# STM32H7RSxx register map
File version: 0.1
CPU: CM7 r0p1, little endian, MPU, FPU, 4 interrupt priority bits
Registers are 32-bit, read-write, reset 0x0 unless marked. A register's access mark holds for its fields unless they carry their own. Offsets are from the block's base; [hi:lo] are bit positions; {n}, {i} and the like mark numbered series.

## RCC
Base 0x58024400
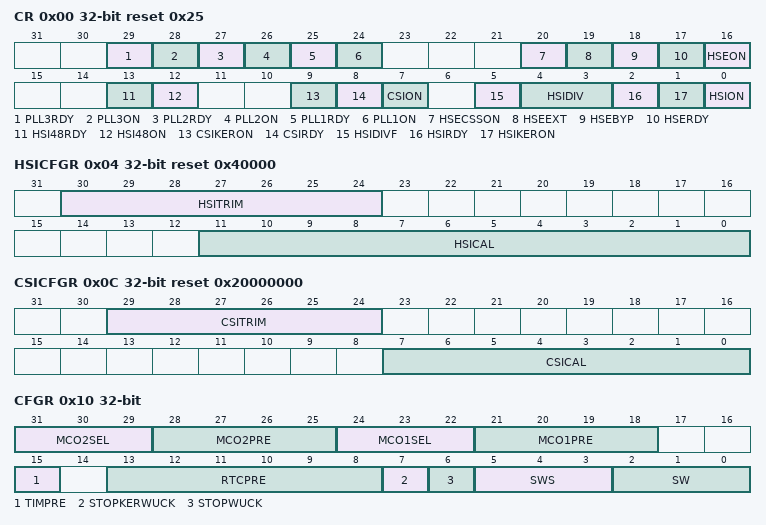
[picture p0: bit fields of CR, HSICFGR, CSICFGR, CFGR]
0x00 CR reset 0x25 — Control register
  [29] PLL3RDY, [28] PLL3ON, [27] PLL2RDY, [26] PLL2ON, [25] PLL1RDY ro, [24] PLL1ON, [20] HSECSSON, [19] HSEEXT, [18] HSEBYP, [17] HSERDY ro, [16] HSEON, [13] HSI48RDY ro, [12] HSI48ON, [9] CSIKERON, [8] CSIRDY ro, [7] CSION, [5] HSIDIVF ro, [4:3] HSIDIV, [2] HSIRDY ro, [1] HSIKERON, [0] HSION
0x04 HSICFGR access not given reset 0x40000 — RCC HSI calibration register
  [30:24] HSITRIM, [11:0] HSICAL
0x08 CRRCR access not given — RCC clock recovery RC register
  [9:0] HSI48CAL
0x0C CSICFGR access not given reset 0x20000000 — RCC CSI calibration register
  [29:24] CSITRIM, [7:0] CSICAL
0x10 CFGR access not given — RCC clock configuration register
  [31:29] MCO2SEL
  [28:25] MCO2PRE
  [24:22] MCO1SEL
  [21:18] MCO1PRE
  [15] TIMPRE
  [13:8] RTCPRE
  [7] STOPKERWUCK — STOPWUCK
  [6] STOPWUCK
  [5:3] SWS ro
  [2:0] SW
0x18 CDCFGR access not given — RCC CPU domain clcok configuration register
  [3:0] CPRE
0x1C BMCFGR access not given — RCC AHB configuration register
  [3:0] BMPRE
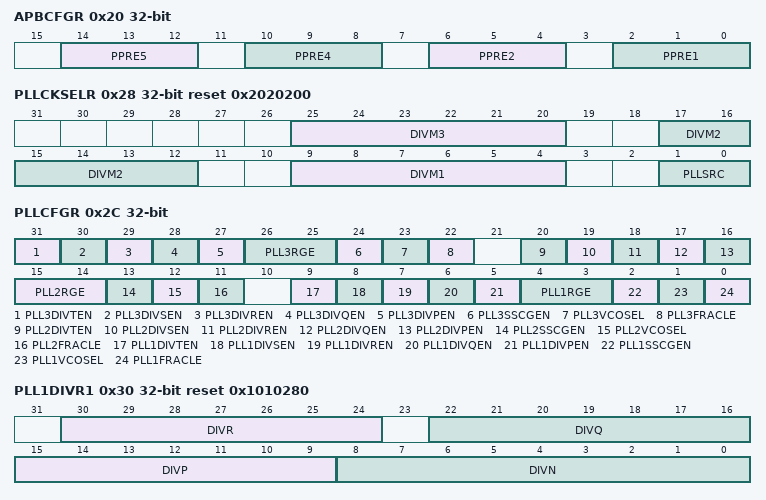
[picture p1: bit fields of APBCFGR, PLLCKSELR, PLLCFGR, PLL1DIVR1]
0x20 APBCFGR access not given — RCC APB clocks configuration register
  [14:12] PPRE5, [10:8] PPRE4, [6:4] PPRE2, [2:0] PPRE1
0x28 PLLCKSELR access not given reset 0x2020200 — RCC PLL clock source selection register
  [25:20] DIVM3 — prescaler for PLL3
  [17:12] DIVM2 — prescaler for PLL2
  [9:4] DIVM1 — prescaler for PLL1
  [1:0] PLLSRC
0x2C PLLCFGR access not given — RCC PLLs configuration register
  [31] PLL3DIVTEN — PLL3 DIVT divider output enable
  [30] PLL3DIVSEN — PLL3 DIVS divider output enable
  [29] PLL3DIVREN — PLL3 DIVR divider output enable
  [28] PLL3DIVQEN — PLL3 DIVQ divider output enable
  [27] PLL3DIVPEN — PLL3 DIVP divider output enable
  [26:25] PLL3RGE — PLL3 input frequency range
  [24] PLL3SSCGEN — PLL3 SSCG enable
  [23] PLL3VCOSEL — PLL3 VCO Selection
  [22] PLL3FRACLE — PLL3 fractionnal latch enable
  [20] PLL2DIVTEN — PLL2 DIVT divider output enable
  [19] PLL2DIVSEN — PLL2 DIVS divider output enable
  [18] PLL2DIVREN — PLL2 DIVR divider output enable
  [17] PLL2DIVQEN — PLL2 DIVQ divider output enable
  [16] PLL2DIVPEN — PLL2 DIVP divider output enable
  [15:14] PLL2RGE — PLL2 input frequency range
  [13] PLL2SSCGEN — PLL2 SSCG enable
  [12] PLL2VCOSEL — PLL2 VCO Selection
  [11] PLL2FRACLE — PLL2 fractionnal latch enable
  [9] PLL1DIVTEN — PLL1 DIVT divider output enable
  [8] PLL1DIVSEN — PLL1 DIVS divider output enable
  [7] PLL1DIVREN — PLL1 DIVR divider output enable
  [6] PLL1DIVQEN — PLL1 DIVQ divider output enable
  [5] PLL1DIVPEN — PLL1 DIVP divider output enable
  [4:3] PLL1RGE — PLL1 input frequency range
  [2] PLL1SSCGEN — PLL1 SSCG enable
  [1] PLL1VCOSEL — PLL1 VCO Selection
  [0] PLL1FRACLE — PLL1 fractionnal latch enable
0x30 PLL1DIVR1 access not given reset 0x1010280 — RCC PLL1 divider configuration register 1
  [30:24] DIVR, [22:16] DIVQ, [15:9] DIVP, [8:0] DIVN
{0x2C+8i} PLL{i}FRACR access not given (i=1..3) — RCC PLL{i} fractional divider register
  [15:3] FRACN
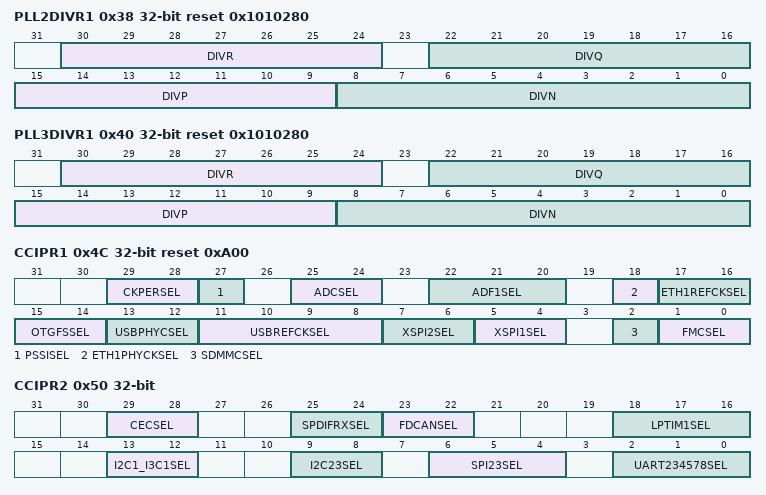
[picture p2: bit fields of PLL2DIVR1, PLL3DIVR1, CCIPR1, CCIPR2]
0x38 PLL2DIVR1 access not given reset 0x1010280 — RCC PLL2 dividers configuration register 1
  [30:24] DIVR, [22:16] DIVQ, [15:9] DIVP, [8:0] DIVN
0x40 PLL3DIVR1 access not given reset 0x1010280 — RCC PLL3 divider configuration register 1
  [30:24] DIVR, [22:16] DIVQ, [15:9] DIVP, [8:0] DIVN
0x4C CCIPR1 access not given reset 0xA00 — RCC AHB peripheral kernel clock selection register
  [29:28] CKPERSEL, [27] PSSISEL, [25:24] ADCSEL, [22:20] ADF1SEL, [18] ETH1PHYCKSEL, [17:16] ETH1REFCKSEL, [15:14] OTGFSSEL, [13:12] USBPHYCSEL, [11:8] USBREFCKSEL, [7:6] XSPI2SEL, [5:4] XSPI1SEL, [2] SDMMCSEL, [1:0] FMCSEL
0x50 CCIPR2 access not given — RCC APB1 peripheral kernel clock selection register
  [29:28] CECSEL, [25:24] SPDIFRXSEL, [23:22] FDCANSEL, [18:16] LPTIM1SEL, [13:12] I2C1_I3C1SEL, [9:8] I2C23SEL, [6:4] SPI23SEL, [2:0] UART234578SEL
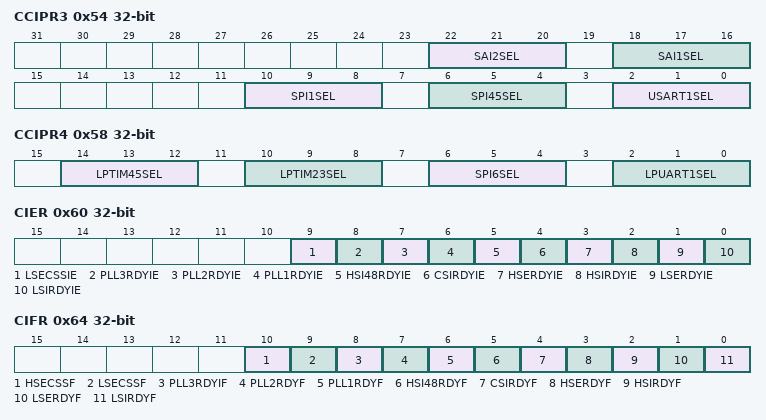
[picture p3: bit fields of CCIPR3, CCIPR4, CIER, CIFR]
0x54 CCIPR3 access not given — RCC APB2 peripheral kernel clock selection register
  [22:20] SAI2SEL, [18:16] SAI1SEL, [10:8] SPI1SEL, [6:4] SPI45SEL, [2:0] USART1SEL
0x58 CCIPR4 access not given — RCC APB4,5 peripheral kernel clock selection register
  [14:12] LPTIM45SEL, [10:8] LPTIM23SEL, [6:4] SPI6SEL, [2:0] LPUART1SEL
0x60 CIER access not given — RCC clock source interrupt enable register
  [9] LSECSSIE, [8] PLL3RDYIE, [7] PLL2RDYIE, [6] PLL1RDYIE, [5] HSI48RDYIE, [4] CSIRDYIE, [3] HSERDYIE, [2] HSIRDYIE, [1] LSERDYIE, [0] LSIRDYIE
0x64 CIFR ro — RCC clock source interrupt flag register
  [10] HSECSSF — LSECSSIF
  [9] LSECSSF
  [8] PLL3RDYIF
  [7] PLL2RDYF
  [6] PLL1RDYF
  [5] HSI48RDYF
  [4] CSIRDYF
  [3] HSERDYF
  [2] HSIRDYF
  [1] LSERDYF
  [0] LSIRDYF
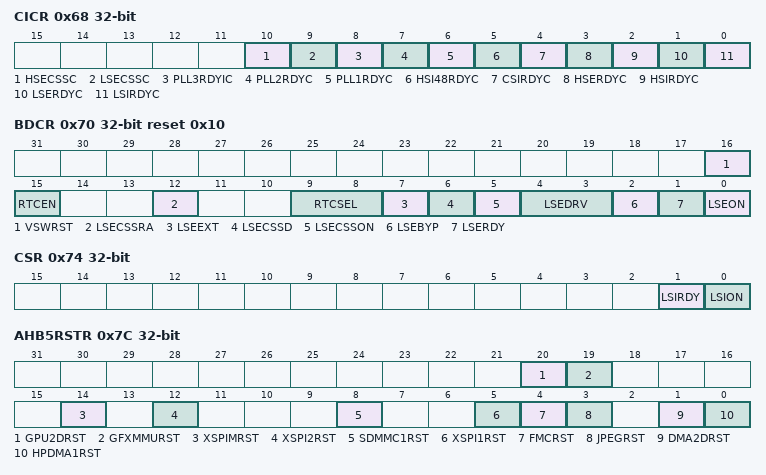
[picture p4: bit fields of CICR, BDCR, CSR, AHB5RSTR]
0x68 CICR access not given — RCC clock source interrupt clear register
  [10] HSECSSC — LSECSSIC
  [9] LSECSSC
  [8] PLL3RDYIC
  [7] PLL2RDYC
  [6] PLL1RDYC
  [5] HSI48RDYC
  [4] CSIRDYC
  [3] HSERDYC
  [2] HSIRDYC
  [1] LSERDYC
  [0] LSIRDYC
0x70 BDCR access not given reset 0x10 — RCC Backup domain control register
  [16] VSWRST, [15] RTCEN, [12] LSECSSRA, [9:8] RTCSEL, [7] LSEEXT, [6] LSECSSD, [5] LSECSSON, [4:3] LSEDRV, [2] LSEBYP, [1] LSERDY ro, [0] LSEON
0x74 CSR access not given — RCC clock control and status register
  [1] LSIRDY ro, [0] LSION
0x7C AHB5RSTR access not given — RCC AHB5 peripheral reset register
  [20] GPU2DRST, [19] GFXMMURST, [14] XSPIMRST, [12] XSPI2RST, [8] SDMMC1RST, [5] XSPI1RST, [4] FMCRST, [3] JPEGRST, [1] DMA2DRST, [0] HPDMA1RST
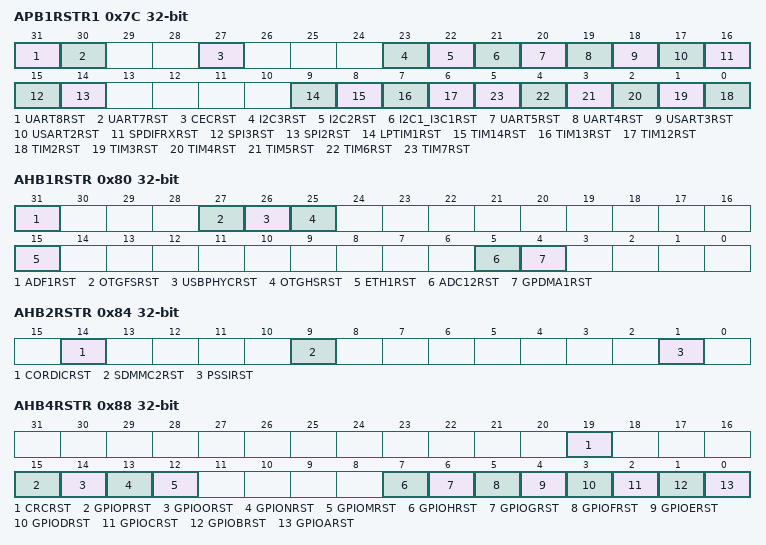
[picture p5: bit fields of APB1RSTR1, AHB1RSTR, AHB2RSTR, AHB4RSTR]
0x7C APB1RSTR1 access not given — RCC APB1 peripheral reset register 1
  [31] UART8RST, [30] UART7RST, [27] CECRST, [23] I2C3RST, [22] I2C2RST, [21] I2C1_I3C1RST, [20] UART5RST, [19] UART4RST, [18] USART3RST, [17] USART2RST, [16] SPDIFRXRST, [15] SPI3RST, [14] SPI2RST, [9] LPTIM1RST, [8] TIM14RST, [7] TIM13RST, [6] TIM12RST, [n-2] TIM{n}RST (n=2..7)
0x80 AHB1RSTR access not given — RCC AHB1 peripheral reset register
  [31] ADF1RST, [27] OTGFSRST, [26] USBPHYCRST, [25] OTGHSRST, [15] ETH1RST, [5] ADC12RST, [4] GPDMA1RST
0x84 AHB2RSTR access not given — RCC AHB2 peripheral reset register
  [14] CORDICRST, [9] SDMMC2RST, [1] PSSIRST
0x88 AHB4RSTR access not given — RCC AHB4 peripheral reset register
  [19] CRCRST, [15] GPIOPRST, [14] GPIOORST, [13] GPIONRST, [12] GPIOMRST, [7] GPIOHRST, [6] GPIOGRST, [5] GPIOFRST, [4] GPIOERST, [3] GPIODRST, [2] GPIOCRST, [1] GPIOBRST, [0] GPIOARST
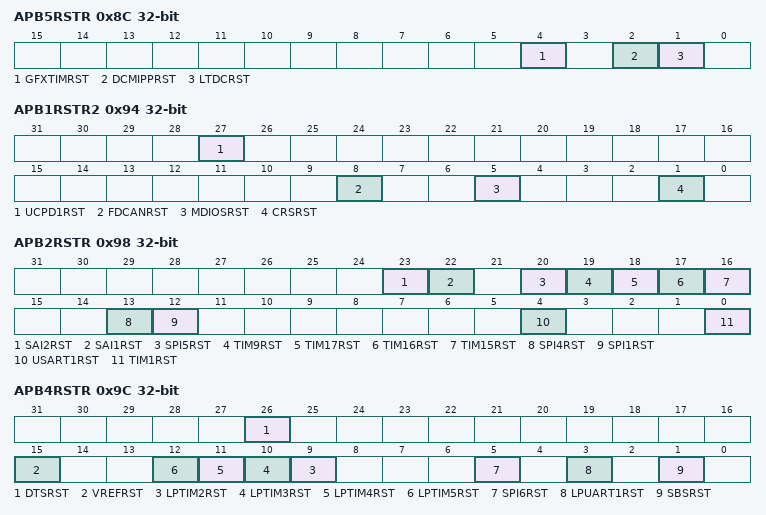
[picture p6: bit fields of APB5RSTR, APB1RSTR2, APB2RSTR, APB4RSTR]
0x8C APB5RSTR access not given — RCC APB5 peripheral reset register
  [4] GFXTIMRST, [2] DCMIPPRST, [1] LTDCRST
0x94 APB1RSTR2 access not given — RCC APB1 peripheral reset register 2
  [27] UCPD1RST, [8] FDCANRST, [5] MDIOSRST, [1] CRSRST
0x98 APB2RSTR access not given — RCC APB2 peripheral reset register
  [23] SAI2RST, [22] SAI1RST, [20] SPI5RST, [19] TIM9RST, [18] TIM17RST, [17] TIM16RST, [16] TIM15RST, [13] SPI4RST, [12] SPI1RST, [4] USART1RST, [0] TIM1RST
0x9C APB4RSTR access not given — RCC APB4 peripheral reset register
  [26] DTSRST, [15] VREFRST, [n+7] LPTIM{n}RST (n=2..5), [5] SPI6RST, [3] LPUART1RST, [1] SBSRST
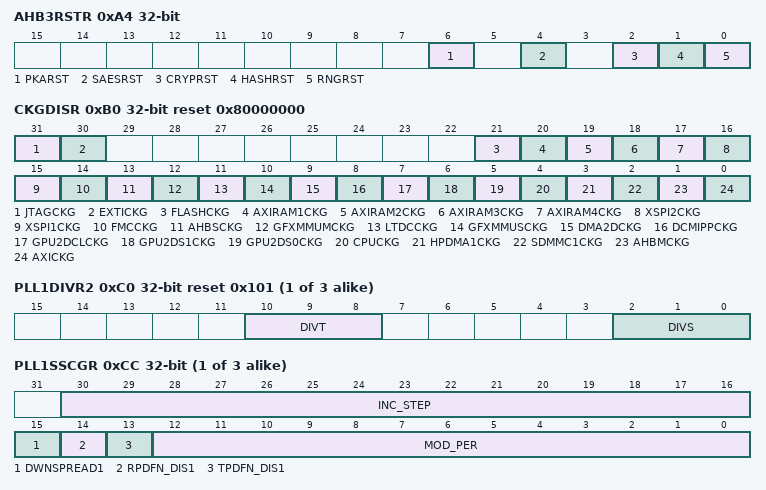
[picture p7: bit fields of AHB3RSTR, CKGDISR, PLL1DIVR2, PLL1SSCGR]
0xA4 AHB3RSTR access not given — RCC AHB3 peripheral reset register
  [6] PKARST, [4] SAESRST, [2] CRYPRST, [1] HASHRST, [0] RNGRST
0xB0 CKGDISR access not given reset 0x80000000 — RCC AXI clocks gating disable register
  [31] JTAGCKG, [30] EXTICKG, [21] FLASHCKG, [21-n] AXIRAM{n}CKG (n=1..4), [16] XSPI2CKG, [15] XSPI1CKG, [14] FMCCKG, [13] AHBSCKG, [12] GFXMMUMCKG, [11] LTDCCKG, [10] GFXMMUSCKG, [9] DMA2DCKG, [8] DCMIPPCKG, [7] GPU2DCLCKG, [6] GPU2DS1CKG, [5] GPU2DS0CKG, [4] CPUCKG, [3] HPDMA1CKG, [2] SDMMC1CKG, [1] AHBMCKG, [0] AXICKG
{0xBC+4i} PLL{i}DIVR2 access not given reset 0x101 (i=1..3) — RCC PLL{i} divider configuration register 2
  [10:8] DIVT, [2:0] DIVS
{0xC8+4i} PLL{i}SSCGR access not given (i=1..3) — PLL{i} Spred Spectrum Clock Generator register
  [30:16] INC_STEP, [15] DWNSPREAD1, [14] RPDFN_DIS1, [13] TPDFN_DIS1, [12:0] MOD_PER
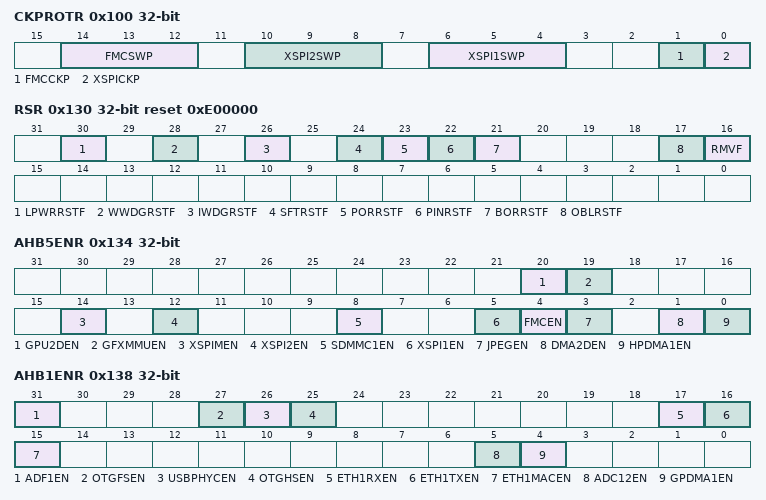
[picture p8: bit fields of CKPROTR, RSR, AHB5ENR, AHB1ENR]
0x100 CKPROTR — RCC clock protection regsiter
  [14:12] FMCSWP — FMC kernel clock switch position
  [10:8] XSPI2SWP — XSPI2 kernel clock switch position
  [6:4] XSPI1SWP — XSPI1 kernel clock switch position
  [1] FMCCKP — FMC clock protection
  [0] XSPICKP — XSPI clock protection
0x130 RSR access not given reset 0xE00000 — RCC Reset status register
  [30] LPWRRSTF, [28] WWDGRSTF, [26] IWDGRSTF, [24] SFTRSTF, [23] PORRSTF, [22] PINRSTF, [21] BORRSTF, [17] OBLRSTF, [16] RMVF
0x134 AHB5ENR access not given — RCC AHB5 clock enable register
  [20] GPU2DEN, [19] GFXMMUEN, [14] XSPIMEN, [12] XSPI2EN, [8] SDMMC1EN, [5] XSPI1EN, [4] FMCEN, [3] JPEGEN, [1] DMA2DEN, [0] HPDMA1EN
0x138 AHB1ENR access not given — RCC AHB1 clock enable register
  [31] ADF1EN, [27] OTGFSEN, [26] USBPHYCEN, [25] OTGHSEN, [17] ETH1RXEN, [16] ETH1TXEN, [15] ETH1MACEN, [5] ADC12EN, [4] GPDMA1EN
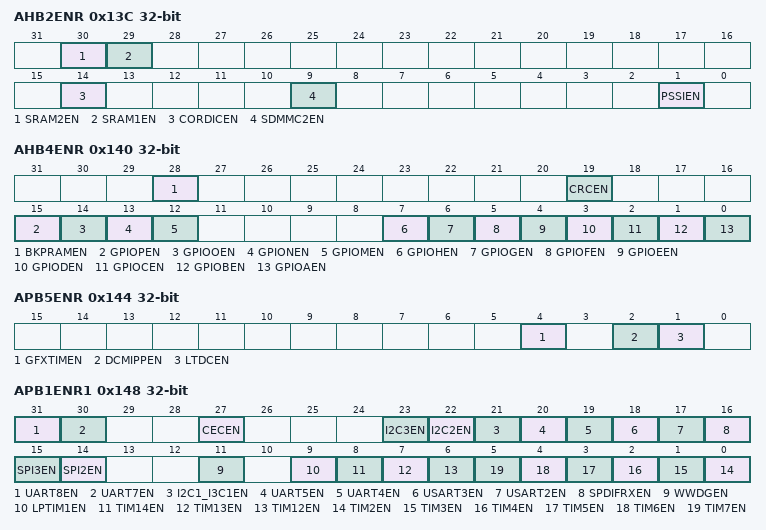
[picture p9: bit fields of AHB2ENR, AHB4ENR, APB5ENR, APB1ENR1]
0x13C AHB2ENR access not given — RCC AHB2 clock enable register
  [30] SRAM2EN, [29] SRAM1EN, [14] CORDICEN, [9] SDMMC2EN, [1] PSSIEN
0x140 AHB4ENR access not given — RCC AHB4 clock enable register
  [28] BKPRAMEN, [19] CRCEN, [15] GPIOPEN, [14] GPIOOEN, [13] GPIONEN, [12] GPIOMEN, [7] GPIOHEN, [6] GPIOGEN, [5] GPIOFEN, [4] GPIOEEN, [3] GPIODEN, [2] GPIOCEN, [1] GPIOBEN, [0] GPIOAEN
0x144 APB5ENR access not given — RCC APB5 clock enable register
  [4] GFXTIMEN, [2] DCMIPPEN, [1] LTDCEN
0x148 APB1ENR1 access not given — RCC APB1 clock enable register 1
  [31] UART8EN, [30] UART7EN, [27] CECEN, [23] I2C3EN, [22] I2C2EN, [21] I2C1_I3C1EN, [20] UART5EN, [19] UART4EN, [18] USART3EN, [17] USART2EN, [16] SPDIFRXEN, [15] SPI3EN, [14] SPI2EN, [11] WWDGEN, [9] LPTIM1EN, [8] TIM14EN, [7] TIM13EN, [6] TIM12EN, [n-2] TIM{n}EN (n=2..7)
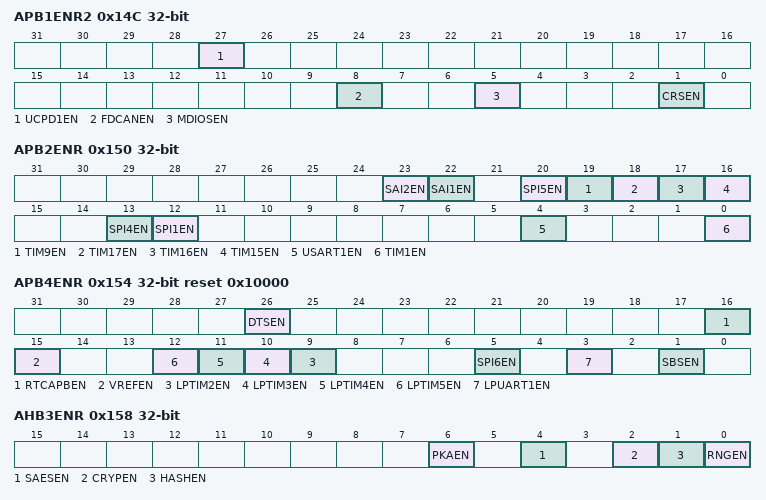
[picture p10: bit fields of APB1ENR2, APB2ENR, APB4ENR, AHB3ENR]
0x14C APB1ENR2 access not given — RCC APB1 clock enable register 2
  [27] UCPD1EN, [8] FDCANEN, [5] MDIOSEN, [1] CRSEN
0x150 APB2ENR access not given — RCC APB2 clock enable register
  [23] SAI2EN, [22] SAI1EN, [20] SPI5EN, [19] TIM9EN, [18] TIM17EN, [17] TIM16EN, [16] TIM15EN, [13] SPI4EN, [12] SPI1EN, [4] USART1EN, [0] TIM1EN
0x154 APB4ENR access not given reset 0x10000 — RCC APB4 clock enable register
  [26] DTSEN, [16] RTCAPBEN, [15] VREFEN, [n+7] LPTIM{n}EN (n=2..5), [5] SPI6EN, [3] LPUART1EN, [1] SBSEN
0x158 AHB3ENR access not given — RCC AHB3 clock enable register
  [6] PKAEN, [4] SAESEN, [2] CRYPEN, [1] HASHEN, [0] RNGEN
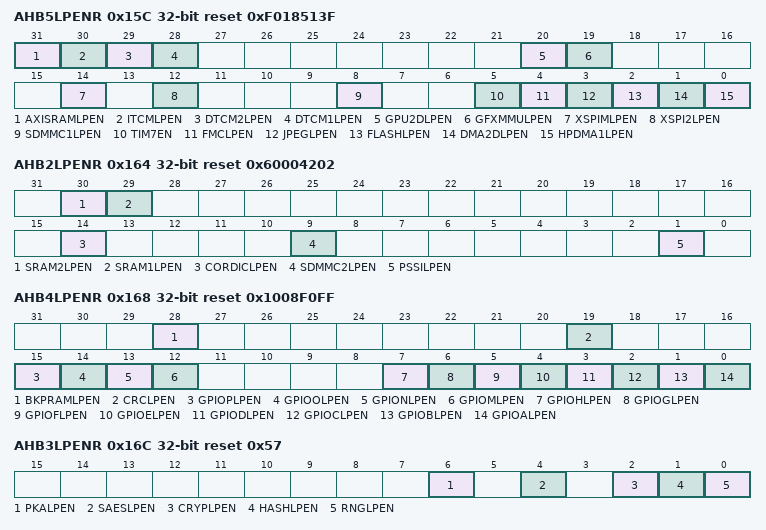
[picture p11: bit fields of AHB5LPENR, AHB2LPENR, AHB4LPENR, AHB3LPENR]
0x15C AHB5LPENR access not given reset 0xF018513F — RCC AHB5 low-power clock enable register
  [31] AXISRAMLPEN, [30] ITCMLPEN, [29] DTCM2LPEN, [28] DTCM1LPEN, [20] GPU2DLPEN, [19] GFXMMULPEN, [14] XSPIMLPEN, [12] XSPI2LPEN, [8] SDMMC1LPEN, [5] TIM7EN, [4] FMCLPEN, [3] JPEGLPEN, [2] FLASHLPEN, [1] DMA2DLPEN, [0] HPDMA1LPEN
0x160 AHB1LPENR access not given reset 0x8E038030 — RCC AHB1 low-power clock enable register
  [31] ADF1LPEN, [27] OTGFSLPEN, [26] USBPHYCLPEN, [25] USBPDCTRL, [25] OTGHSLPEN, [17] ETH1RXLPEN, [16] ETH1TXLPEN, [15] ETH1MACLPEN, [5] ADC12LPEN, [4] GPDMA1LPEN
0x164 AHB2LPENR access not given reset 0x60004202 — RCC AHB2 low-power clock enable register
  [30] SRAM2LPEN, [29] SRAM1LPEN, [14] CORDICLPEN, [9] SDMMC2LPEN, [1] PSSILPEN
0x168 AHB4LPENR access not given reset 0x1008F0FF — RCC AHB4 low-power clock enable register
  [28] BKPRAMLPEN, [19] CRCLPEN, [15] GPIOPLPEN, [14] GPIOOLPEN, [13] GPIONLPEN, [12] GPIOMLPEN, [7] GPIOHLPEN, [6] GPIOGLPEN, [5] GPIOFLPEN, [4] GPIOELPEN, [3] GPIODLPEN, [2] GPIOCLPEN, [1] GPIOBLPEN, [0] GPIOALPEN
0x16C AHB3LPENR access not given reset 0x57 — RCC AHB3 low-power clock enable register
  [6] PKALPEN, [4] SAESLPEN, [2] CRYPLPEN, [1] HASHLPEN, [0] RNGLPEN
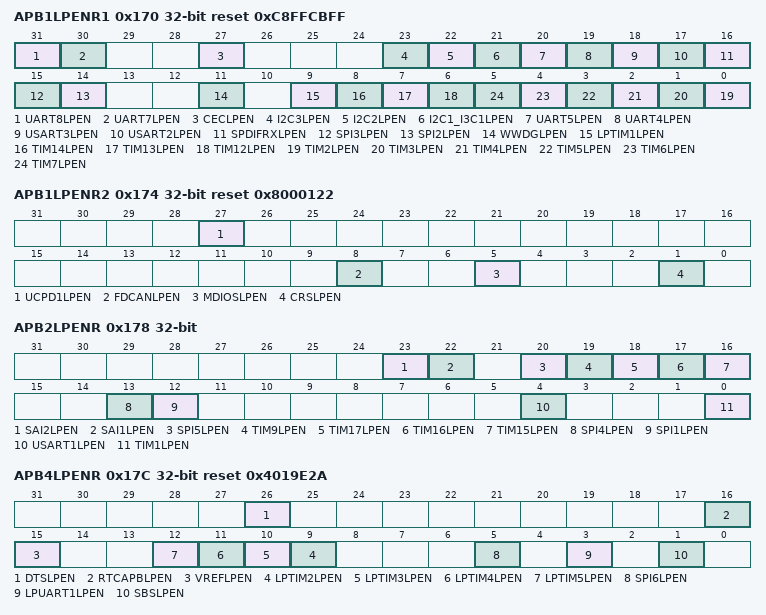
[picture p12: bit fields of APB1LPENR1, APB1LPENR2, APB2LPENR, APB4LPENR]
0x170 APB1LPENR1 access not given reset 0xC8FFCBFF — RCC APB1 low-power clock enable register 1
  [31] UART8LPEN, [30] UART7LPEN, [27] CECLPEN, [23] I2C3LPEN, [22] I2C2LPEN, [21] I2C1_I3C1LPEN, [20] UART5LPEN, [19] UART4LPEN, [18] USART3LPEN, [17] USART2LPEN, [16] SPDIFRXLPEN, [15] SPI3LPEN, [14] SPI2LPEN, [11] WWDGLPEN, [9] LPTIM1LPEN, [8] TIM14LPEN, [7] TIM13LPEN, [6] TIM12LPEN, [n-2] TIM{n}LPEN (n=2..7)
0x174 APB1LPENR2 access not given reset 0x8000122 — RCC APB1 low-power clock enable register 2
  [27] UCPD1LPEN, [8] FDCANLPEN, [5] MDIOSLPEN, [1] CRSLPEN
0x178 APB2LPENR access not given reset not defined — RCC APB2 low-power clock enable register
  [23] SAI2LPEN, [22] SAI1LPEN, [20] SPI5LPEN, [19] TIM9LPEN, [18] TIM17LPEN, [17] TIM16LPEN, [16] TIM15LPEN, [13] SPI4LPEN, [12] SPI1LPEN, [4] USART1LPEN, [0] TIM1LPEN
0x17C APB4LPENR access not given reset 0x4019E2A — RCC APB4 low-power clock enable register
  [26] DTSLPEN, [16] RTCAPBLPEN, [15] VREFLPEN, [n+7] LPTIM{n}LPEN (n=2..5), [5] SPI6LPEN, [3] LPUART1LPEN, [1] SBSLPEN
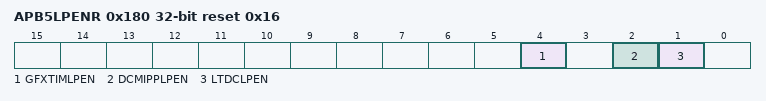
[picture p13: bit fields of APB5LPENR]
0x180 APB5LPENR access not given reset 0x16 — RCC APB5 low-power clock enable register
  [4] GFXTIMLPEN, [2] DCMIPPLPEN, [1] LTDCLPEN
